# XMC4300 register map
Vendor: Infineon; File version: 1.1.0 (Reference Manual v1.1)
CPU: CM4 r2p0, little endian, MPU, FPU, 6 interrupt priority bits
Registers are 32-bit, read-write, reset 0x0 unless marked. A register's access mark holds for its fields unless they carry their own. Offsets are from the block's base; [hi:lo] are bit positions; {n}, {i} and the like mark numbered series.

## PORT4
Base 0x48028400
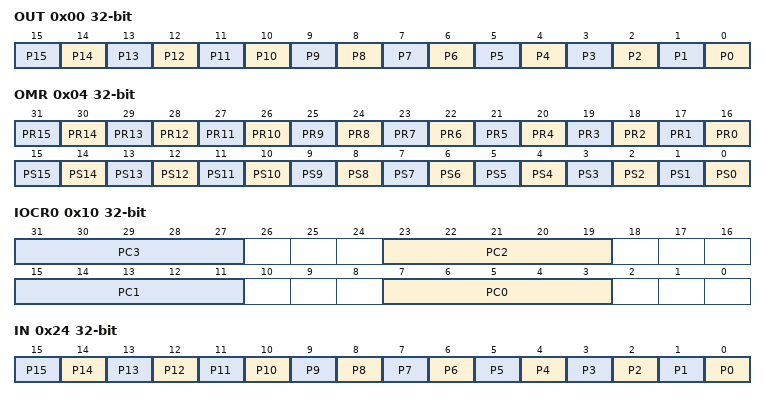
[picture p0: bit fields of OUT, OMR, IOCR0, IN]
0x00 OUT — Port 4 Output Register
  [all] fields
    0=Const_0 (The output level of Pn.x is 0.); 1=Const_1 (The output level of Pn.x is 1.)
  [n] P{n} read-modifies (n=0..15) — Port n Output Bit {n}
0x04 OMR wo — Port 4 Output Modification Register
  [n+16] PR{n} (n=0..15) — Port n Reset Bit {n}
  [n] PS{n} (n=0..15) — Port n Set Bit {n}
0x10 IOCR0 — Port 4 Input/Output Control Register 0
  [8n+7:8n+3] PC{n} (n=0..3) — Port Control for Port n Pin 0 to 3
0x24 IN ro (reset mask 0xFFFF0000) — Port 4 Input Register
  [all] fields
    0=Const_0 (The input level of Pn.x is 0.); 1=Const_1 (The input level of Pn.x is 1.)
  [n] P{n} read-modifies (n=0..15) — Port n Input Bit {n}
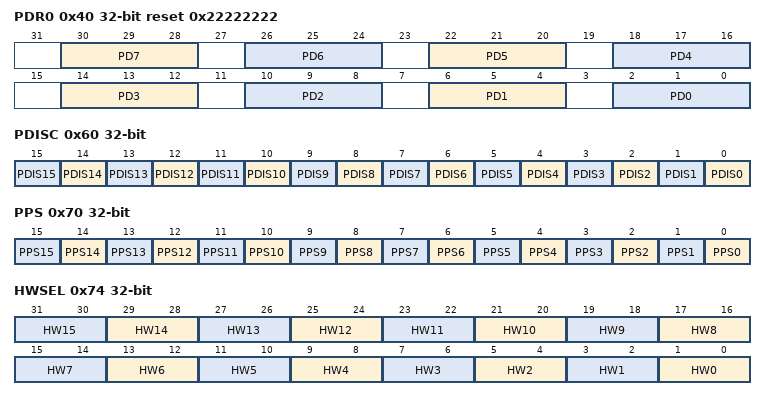
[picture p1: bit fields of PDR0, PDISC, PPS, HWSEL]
0x40 PDR0 reset 0x22222222 — Port 4 Pad Driver Mode 0 Register
  [30:28] PD7 — Pad Driver Mode for Pn.7
  [26:24] PD6 — Pad Driver Mode for Pn.6
  [22:20] PD5 — Pad Driver Mode for Pn.5
  [18:16] PD4 — Pad Driver Mode for Pn.4
  [14:12] PD3 — Pad Driver Mode for Pn.3
  [10:8] PD2 — Pad Driver Mode for Pn.2
  [6:4] PD1 — Pad Driver Mode for Pn.1
  [2:0] PD0 — Pad Driver Mode for Pn.0
0x60 PDISC ro (reset mask 0xFFFF0000) — Port 4 Pin Function Decision Control Register
  [all] fields
    0=Const_0 (Pad Pn.x is enabled.); 1=Const_1 (Pad Pn.x is disabled.)
  [n] PDIS{n} (n=0..15) — Pad Disable for Port n Pin {n}
0x70 PPS — Port 4 Pin Power Save Register
  [all] fields
    0=Const_0 (Pin Power Save of Pn.x is disabled.); 1=Const_1 (Pin Power Save of Pn.x is enabled.)
  [n] PPS{n} (n=0..15) — Port n Pin Power Save Bit {n}
0x74 HWSEL — Port 4 Pin Hardware Select Register
  [all] fields
    0=Const_00 (Software control only.); 1=Const_01 (HWI0/HWO0 control path can override the software configuration.); 2=Const_10 (HWI1/HWO1 control path can override the software configuration.)
  [2n+1:2n] HW{n} (n=0..15) — Port n Pin Hardware Select Bit {n}

## PORT5
Base 0x48028500
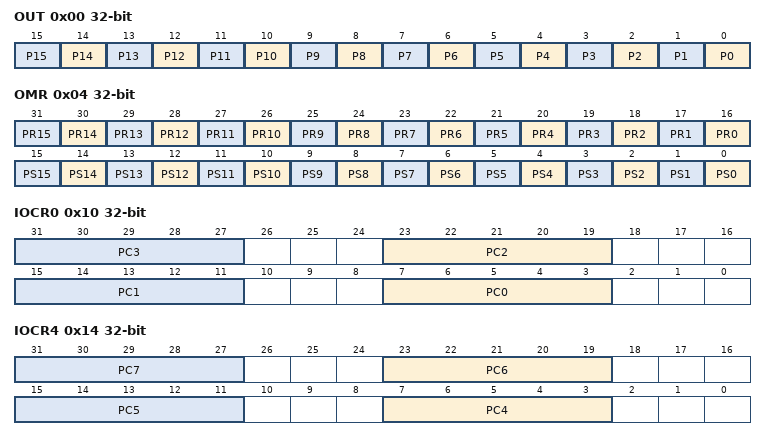
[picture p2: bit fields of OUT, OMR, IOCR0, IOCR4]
0x00 OUT — Port 5 Output Register
  [all] fields
    0=Const_0 (The output level of Pn.x is 0.); 1=Const_1 (The output level of Pn.x is 1.)
  [n] P{n} read-modifies (n=0..15) — Port n Output Bit {n}
0x04 OMR wo — Port 5 Output Modification Register
  [n+16] PR{n} (n=0..15) — Port n Reset Bit {n}
  [n] PS{n} (n=0..15) — Port n Set Bit {n}
0x10 IOCR0 — Port 5 Input/Output Control Register 0
  [8n+7:8n+3] PC{n} (n=0..3) — Port Control for Port n Pin 0 to 3
0x14 IOCR4 — Port 5 Input/Output Control Register 4
  [8n-25:8n-29] PC{n} (n=4..7) — Port Control for Port n Pin 4 to 7
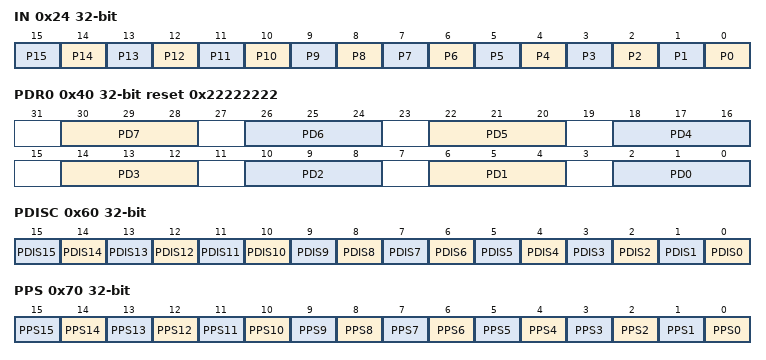
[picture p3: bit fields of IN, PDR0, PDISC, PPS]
0x24 IN ro (reset mask 0xFFFF0000) — Port 5 Input Register
  [all] fields
    0=Const_0 (The input level of Pn.x is 0.); 1=Const_1 (The input level of Pn.x is 1.)
  [n] P{n} read-modifies (n=0..15) — Port n Input Bit {n}
0x40 PDR0 reset 0x22222222 — Port 5 Pad Driver Mode 0 Register
  [30:28] PD7 — Pad Driver Mode for Pn.7
  [26:24] PD6 — Pad Driver Mode for Pn.6
  [22:20] PD5 — Pad Driver Mode for Pn.5
  [18:16] PD4 — Pad Driver Mode for Pn.4
  [14:12] PD3 — Pad Driver Mode for Pn.3
  [10:8] PD2 — Pad Driver Mode for Pn.2
  [6:4] PD1 — Pad Driver Mode for Pn.1
  [2:0] PD0 — Pad Driver Mode for Pn.0
0x60 PDISC ro (reset mask 0xFFFF0000) — Port 5 Pin Function Decision Control Register
  [all] fields
    0=Const_0 (Pad Pn.x is enabled.); 1=Const_1 (Pad Pn.x is disabled.)
  [n] PDIS{n} (n=0..15) — Pad Disable for Port n Pin {n}
0x70 PPS — Port 5 Pin Power Save Register
  [all] fields
    0=Const_0 (Pin Power Save of Pn.x is disabled.); 1=Const_1 (Pin Power Save of Pn.x is enabled.)
  [n] PPS{n} (n=0..15) — Port n Pin Power Save Bit {n}
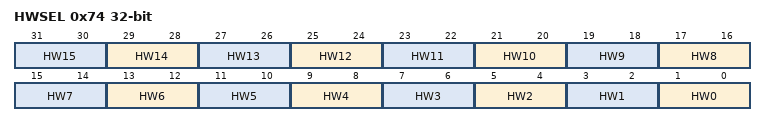
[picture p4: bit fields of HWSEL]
0x74 HWSEL — Port 5 Pin Hardware Select Register
  [all] fields
    0=Const_00 (Software control only.); 1=Const_01 (HWI0/HWO0 control path can override the software configuration.); 2=Const_10 (HWI1/HWO1 control path can override the software configuration.)
  [2n+1:2n] HW{n} (n=0..15) — Port n Pin Hardware Select Bit {n}
